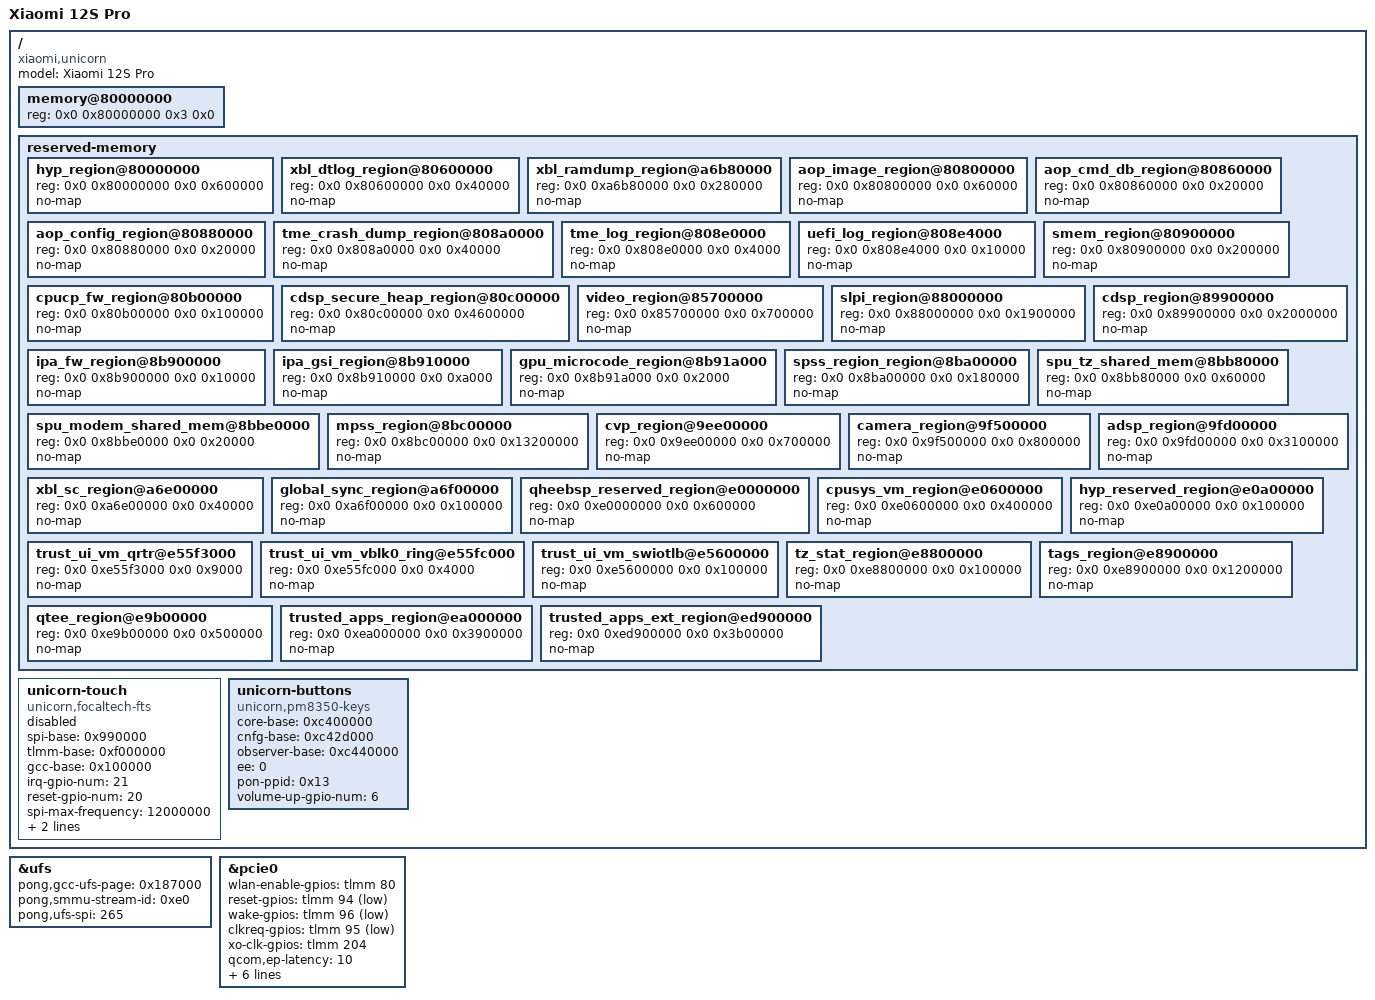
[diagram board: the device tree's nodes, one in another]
/*
 * unicorn（Xiaomi 12S Pro，2206122SC，SM8475 / taro）
 *
 * 本文件的板级数值全部来自本机实测（不是兄弟设备抄来的）：
 *   数据来源：/mnt/d/iOS/unicorn-port/data/unicorn-<时间戳>/
 *     live-fdt.dts         —— 本机 live device tree（由 /sys/firmware/fdt 反编译）
 *     proc-iomem.txt       —— 本机物理地址映射
 *     input-devices.txt    —— fts / pmic_* / gpio-keys 输入设备
 *     getprop.txt          —— unicorn / SM8475 / slot _a
 *   交叉验证：MemTotal 11444364 kB → 12 GiB 物理 DRAM，与 pong/thor 同族
 *
 * 仍为「同 SoC 继承值、待实测确认」的项都在行内标了 TODO(verify)。
 */

/dts-v1/;
/include/ "sm8475.dtsi"
/ {
    model = "Xiaomi 12S Pro";
    compatible = "xiaomi,unicorn", "qcom,sm8475";

    /* 12 GiB 物理 DRAM，基址 0x80000000（本机 memory 节点 ddr_size = 0x0c，
       MemTotal 11.4 GB；XNU 需要一段连续窗口，与 pong/thor 的写法一致）。 */
    memory@80000000 { device_type = "memory"; reg = <0x0 0x80000000 0x3 0x0>; };

    /* 以下 36 个保留区逐个抄自本机 reserved-memory（原样保留 href 名与 reg）。 */
    reserved-memory {
        #address-cells = <2>;
        #size-cells = <2>;
        ranges;
        hyp_region@80000000 { reg = <0x0 0x80000000 0x0 0x600000>; no-map; };
        xbl_dtlog_region@80600000 { reg = <0x0 0x80600000 0x0 0x40000>; no-map; };
        xbl_ramdump_region@a6b80000 { reg = <0x0 0xa6b80000 0x0 0x280000>; no-map; };
        aop_image_region@80800000 { reg = <0x0 0x80800000 0x0 0x60000>; no-map; };
        aop_cmd_db_region@80860000 { reg = <0x0 0x80860000 0x0 0x20000>; no-map; };
        aop_config_region@80880000 { reg = <0x0 0x80880000 0x0 0x20000>; no-map; };
        tme_crash_dump_region@808a0000 { reg = <0x0 0x808a0000 0x0 0x40000>; no-map; };
        tme_log_region@808e0000 { reg = <0x0 0x808e0000 0x0 0x4000>; no-map; };
        uefi_log_region@808e4000 { reg = <0x0 0x808e4000 0x0 0x10000>; no-map; };
        smem_region@80900000 { reg = <0x0 0x80900000 0x0 0x200000>; no-map; };
        cpucp_fw_region@80b00000 { reg = <0x0 0x80b00000 0x0 0x100000>; no-map; };
        cdsp_secure_heap_region@80c00000 { reg = <0x0 0x80c00000 0x0 0x4600000>; no-map; };
        video_region@85700000 { reg = <0x0 0x85700000 0x0 0x700000>; no-map; };
        slpi_region@88000000 { reg = <0x0 0x88000000 0x0 0x1900000>; no-map; };
        cdsp_region@89900000 { reg = <0x0 0x89900000 0x0 0x2000000>; no-map; };
        ipa_fw_region@8b900000 { reg = <0x0 0x8b900000 0x0 0x10000>; no-map; };
        ipa_gsi_region@8b910000 { reg = <0x0 0x8b910000 0x0 0xa000>; no-map; };
        gpu_microcode_region@8b91a000 { reg = <0x0 0x8b91a000 0x0 0x2000>; no-map; };
        spss_region_region@8ba00000 { reg = <0x0 0x8ba00000 0x0 0x180000>; no-map; };
        spu_tz_shared_mem@8bb80000 { reg = <0x0 0x8bb80000 0x0 0x60000>; no-map; };
        spu_modem_shared_mem@8bbe0000 { reg = <0x0 0x8bbe0000 0x0 0x20000>; no-map; };
        mpss_region@8bc00000 { reg = <0x0 0x8bc00000 0x0 0x13200000>; no-map; };
        cvp_region@9ee00000 { reg = <0x0 0x9ee00000 0x0 0x700000>; no-map; };
        camera_region@9f500000 { reg = <0x0 0x9f500000 0x0 0x800000>; no-map; };
        adsp_region@9fd00000 { reg = <0x0 0x9fd00000 0x0 0x3100000>; no-map; };
        xbl_sc_region@a6e00000 { reg = <0x0 0xa6e00000 0x0 0x40000>; no-map; };
        global_sync_region@a6f00000 { reg = <0x0 0xa6f00000 0x0 0x100000>; no-map; };
        qheebsp_reserved_region@e0000000 { reg = <0x0 0xe0000000 0x0 0x600000>; no-map; };
        cpusys_vm_region@e0600000 { reg = <0x0 0xe0600000 0x0 0x400000>; no-map; };
        hyp_reserved_region@e0a00000 { reg = <0x0 0xe0a00000 0x0 0x100000>; no-map; };
        trust_ui_vm_qrtr@e55f3000 { reg = <0x0 0xe55f3000 0x0 0x9000>; no-map; };
        trust_ui_vm_vblk0_ring@e55fc000 { reg = <0x0 0xe55fc000 0x0 0x4000>; no-map; };
        trust_ui_vm_swiotlb@e5600000 { reg = <0x0 0xe5600000 0x0 0x100000>; no-map; };
        tz_stat_region@e8800000 { reg = <0x0 0xe8800000 0x0 0x100000>; no-map; };
        tags_region@e8900000 { reg = <0x0 0xe8900000 0x0 0x1200000>; no-map; };
        qtee_region@e9b00000 { reg = <0x0 0xe9b00000 0x0 0x500000>; no-map; };
        trusted_apps_region@ea000000 { reg = <0x0 0xea000000 0x0 0x3900000>; no-map; };
        trusted_apps_ext_region@ed900000 { reg = <0x0 0xed900000 0x0 0x3b00000>; no-map; };
    };

    /* 触摸：FocalTech FTS，SPI(qup) 0x990000 上，IRQ GPIO 21 / RESET GPIO 20，
       fts,x-max 14400 / y-max 32000（面板坐标 1440x3200 的 10 倍定点）。
       目前 UniXNU 侧还没有 fts 驱动，先 disabled；写驱动后打开即可。 */
    unicorn-touch {
        status = "disabled";
        compatible = "unicorn,focaltech-fts";
        spi-base = /bits/ 64 <0x990000>;
        tlmm-base = /bits/ 64 <0xf000000>;
        gcc-base = /bits/ 64 <0x100000>;
        irq-gpio-num = <21>;
        reset-gpio-num = <20>;
        spi-max-frequency = <12000000>;
        max-x = <1440>;
        max-y = <3200>;
    };

    /* 实体键：电源键走 PMK8350 PON（ppid 0x13），音量上走 TLMM GPIO 6（来自 gpio_keys/vol_up）。
       注意：这与 pong 的「音量走 PON ppid 0x18d」不同，是本机的真实差异。 */
    unicorn-buttons {
        compatible = "unicorn,pm8350-keys";
        core-base = /bits/ 64 <0xc400000>;
        cnfg-base = /bits/ 64 <0xc42d000>;
        observer-base = /bits/ 64 <0xc440000>;
        ee = <0>;
        pon-ppid = <0x13>;
        volume-up-gpio-num = <6>;
    };
};

/* UFS：1d84000.ufshc，SMMU StreamID 0xe0，interrupt SPI 0x109，reset GPIO 210。 */
&ufs {
    status = "okay";
    pong,gcc-ufs-page = /bits/ 64 <0x187000>;  /* TODO(verify) 继承 pong 的 GCC UFS 页偏移 */
    pong,smmu-stream-id = <0xe0>;
    pong,ufs-spi = <265>;
};

/* Wi-Fi：QCA6490（cnss-qca6490@b0000000），PCIe RC0 @0x1c00000，
   perst GPIO 94 / wake GPIO 96 / wlan-en GPIO 80。 */
&pcie0 {
    status = "okay";
    wlan-enable-gpios = <&tlmm 80 0>;
    reset-gpios = <&tlmm 94 1>;
    wake-gpios = <&tlmm 96 1>;
    clkreq-gpios = <&tlmm 95 1>;
    xo-clk-gpios = <&tlmm 204 0>;
    qcom,ep-latency = <10>;
    qcom,aux-clk-freq = <20>;
    qcom,phy-status-offset = <0x214>;
    qcom,phy-status-bit = <6>;
    qcom,phy-power-down-offset = <0x240>;
    max-clock-frequency-hz = <0 0 0 19200000 0 0 0 0 0 0 0 100000000 0 0 0>;
    /* TODO(verify) phy-sequence 继承 pong（同为 SM8475 PCIe PHY）；首版先沿用。 */
};
